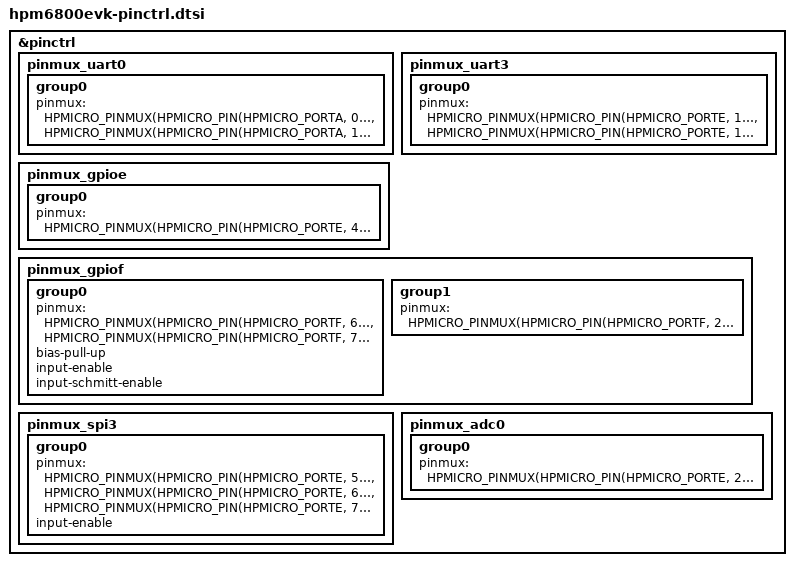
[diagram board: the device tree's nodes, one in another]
/*
 * Copyright 2024 HPMicro
 * SPDX-License-Identifier: Apache-2.0
 */
 
#include "dt-bindings/pinctrl/hpmicro-pinctrl-common.h"

&pinctrl {
	pinmux_uart0: pinmux_uart0 {
		group0 {
			pinmux = <HPMICRO_PINMUX(HPMICRO_PIN(HPMICRO_PORTA, 0), IOC_TYPE_IOC, 0, 2)>,
					 <HPMICRO_PINMUX(HPMICRO_PIN(HPMICRO_PORTA, 1), IOC_TYPE_IOC, 0, 2)>;
		};
	};
	pinmux_uart3: pinmux_uart3 {
		group0 {
			pinmux = <HPMICRO_PINMUX(HPMICRO_PIN(HPMICRO_PORTE, 14), IOC_TYPE_IOC, 0, 2)>,
					 <HPMICRO_PINMUX(HPMICRO_PIN(HPMICRO_PORTE, 15), IOC_TYPE_IOC, 0, 2)>;
		};
	};

	pinmux_gpioe: pinmux_gpioe {
		group0 {
			pinmux = <HPMICRO_PINMUX(HPMICRO_PIN(HPMICRO_PORTE, 4), IOC_TYPE_IOC, 0, 0)>;
		};
	};

	pinmux_gpiof: pinmux_gpiof {
		group0 {
			pinmux = <HPMICRO_PINMUX(HPMICRO_PIN(HPMICRO_PORTF, 6), IOC_TYPE_IOC, 0, 0)>,
					 <HPMICRO_PINMUX(HPMICRO_PIN(HPMICRO_PORTF, 7), IOC_TYPE_IOC, 0, 0)>;
			bias-pull-up;
			input-enable;
			input-schmitt-enable;
		};

		group1 {
			pinmux = <HPMICRO_PINMUX(HPMICRO_PIN(HPMICRO_PORTF, 2), IOC_TYPE_IOC, 0, 0)>;
		};
	};

	pinmux_spi3: pinmux_spi3 {
		group0 {
			pinmux = <HPMICRO_PINMUX(HPMICRO_PIN(HPMICRO_PORTE, 5), IOC_TYPE_IOC, 0, 5)>,
					 <HPMICRO_PINMUX(HPMICRO_PIN(HPMICRO_PORTE, 6), IOC_TYPE_IOC, 0, 5)>,
					 <HPMICRO_PINMUX(HPMICRO_PIN(HPMICRO_PORTE, 7), IOC_TYPE_IOC, 0, 5)>;
					 input-enable;
		};
	};

	pinmux_adc0: pinmux_adc0 {
		group0 {
			pinmux = <HPMICRO_PINMUX(HPMICRO_PIN(HPMICRO_PORTE, 24), IOC_TYPE_IOC, 1, 0)>;
		};
	};
};
